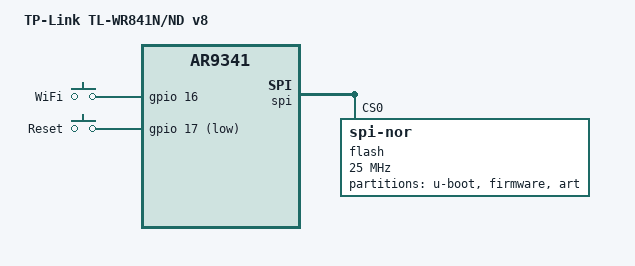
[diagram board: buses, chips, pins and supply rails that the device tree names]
// SPDX-License-Identifier: GPL-2.0-or-later OR MIT

#include "ar9341_tplink.dtsi"

/ {
	model = "TP-Link TL-WR841N/ND v8";
	compatible = "tplink,tl-wr841-v8", "qca,ar9341";

	keys {
		compatible = "gpio-keys";

		rfkill {
			label = "WiFi";
			linux,code = <KEY_RFKILL>;
			linux,input-type = <EV_SW>;
			gpios = <&gpio 16 GPIO_ACTIVE_HIGH>;
			debounce-interval = <60>;
		};

		reset {
			label = "Reset";
			linux,code = <KEY_RESTART>;
			gpios = <&gpio 17 GPIO_ACTIVE_LOW>;
			debounce-interval = <60>;
		};
	};
};

&spi {
	status = "okay";

	flash@0 {
		compatible = "jedec,spi-nor";
		reg = <0>;
		spi-max-frequency = <25000000>;

		partitions {
			compatible = "fixed-partitions";
			#address-cells = <1>;
			#size-cells = <1>;

			uboot: partition@0 {
				label = "u-boot";
				reg = <0x000000 0x020000>;
				read-only;
			};

			partition@20000 {
				compatible = "tplink,firmware";
				label = "firmware";
				reg = <0x020000 0x3d0000>;
			};

			art: partition@3f0000 {
				label = "art";
				reg = <0x3f0000 0x010000>;
				read-only;
			};
		};
	};
};
